# K32W061 register map
Vendor: nxp.com; File version: 1.0
CPU: CM4 r0p1, little endian, MPU, no FPU, VTOR, 3 interrupt priority bits
Registers are 32-bit, read-write, reset 0x0 unless marked. A register's access mark holds for its fields unless they carry their own. Offsets are from the block's base; [hi:lo] are bit positions.

## ASYNC_SYSCON — This is the description of component async_syscon
Base 0x40020000
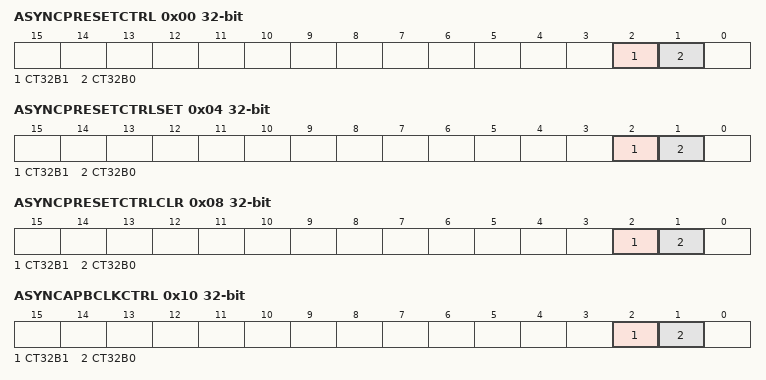
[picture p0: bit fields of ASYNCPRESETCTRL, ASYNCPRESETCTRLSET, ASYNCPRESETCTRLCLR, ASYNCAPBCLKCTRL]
0x00 ASYNCPRESETCTRL — Asynchronous peripherals reset control. The ASYNCPRESETCTRL register allows software to reset specific peripherals attached to the async APB bridge. Writing a zero to any assigned bit in this register clears the reset and allows the specified peripheral to operate. Writing a one asserts the reset.
  [2] CT32B1 — Controls the reset for Counter/Timer CT32B1
    0=CLEAR (Clear reset to Counter/Timer CT32B1.); 1=ASSERT (Assert reset to Counter/Timer CT32B1.)
  [1] CT32B0 — Controls the reset for Counter/Timer CT32B0
    0=CLEAR (Clear reset to Counter/Timer CT32B0.); 1=ASSERT (Assert reset to Counter/Timer CT32B0.)
0x04 ASYNCPRESETCTRLSET reset not defined — Set bits in ASYNCPRESETCTRL. Writing ones to this register sets the corresponding bit or bits in the ASYNCPRESETCTRL register, if they are implemented
  [2] CT32B1 wo — Writing 1 to this register sets the bit ASYNCPRESETCTRL.CT32B1
    0=NO_EFFECT; 1=SET (Set the bit ASYNCPRESETCTRL.CT32B1.)
  [1] CT32B0 wo — Writing 1 to this register sets the bit ASYNCPRESETCTRL.CT32B0
    0=NO_EFFECT; 1=SET (Set the bit ASYNCPRESETCTRL.CT32B0.)
0x08 ASYNCPRESETCTRLCLR reset not defined — Clear bits in ASYNCPRESETCTRL. Writing ones to this register clears the corresponding bit or bits in the ASYNCPRESETCTRL register, if they are implemented
  [2] CT32B1 wo — Writing 1 to this register clears the bit ASYNCPRESETCTRL.CT32B1
    0=NO_EFFECT; 1=CLEAR (Clear the bit ASYNCPRESETCTRL.CT32B1.)
  [1] CT32B0 wo — Writing 1 to this register clears the bit ASYNCPRESETCTRL.CT32B0
    0=NO_EFFECT; 1=CLEAR (Clear the bit ASYNCPRESETCTRL.CT32B0.)
0x10 ASYNCAPBCLKCTRL — Asynchronous peripherals clock control. This register controls how the clock selected for the asynchronous APB peripherals is divided to provide the clock to the asynchronous peripherals
  [2] CT32B1 — Controls the clock for Counter/Timer CT32B1
    0=DISABLE (Disable clock to Counter/Timer CT32B1.); 1=ENABLE (Enable clock to Counter/Timer CT32B1.)
  [1] CT32B0 — Controls the clock for Counter/Timer CT32B0
    0=DISABLE (Disable clock to Counter/Timer CT32B0.); 1=ENABLE (Enable clock to Counter/Timer CT32B0.)
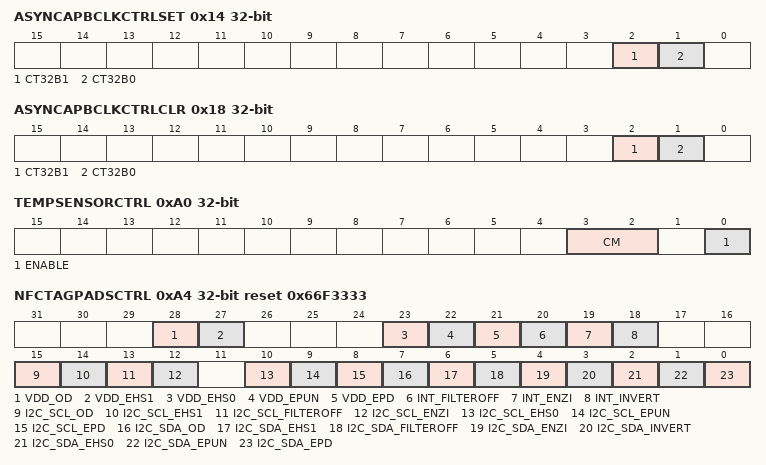
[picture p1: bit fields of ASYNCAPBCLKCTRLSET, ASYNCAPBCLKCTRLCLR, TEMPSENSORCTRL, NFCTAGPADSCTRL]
0x14 ASYNCAPBCLKCTRLSET reset not defined — Set bits in ASYNCAPBCLKCTRL. Writing ones to this register sets the corresponding bit or bits in the ASYNCAPBCLKCTRLSET register, if they are implemented
  [2] CT32B1 wo — Writing 1 to this register sets the bit ASYNCAPBCLKCTRL.CT32B1
    0=NO_EFFECT; 1=SET (Set the bit ASYNCAPBCLKCTRL.CT32B1.)
  [1] CT32B0 wo — Writing 1 to this register sets the bit ASYNCAPBCLKCTRL.CT32B0
    0=NO_EFFECT; 1=SET (Set the bit ASYNCAPBCLKCTRL.CT32B0.)
0x18 ASYNCAPBCLKCTRLCLR reset not defined — Clear bits in ASYNCAPBCLKCTRL. Writing ones to this register sets the corresponding bit or bits in the ASYNCAPBCLKCTRLSET register, if they are implemented
  [2] CT32B1 wo — Writing 1 to this register clears the bit ASYNCAPBCLKCTRL.CT32B1
    0=NO_EFFECT; 1=CLEAR (Clear the bit ASYNCAPBCLKCTRL.CT32B1.)
  [1] CT32B0 wo — Writing 1 to this register clears the bit ASYNCAPBCLKCTRL.CT32B0
    0=NO_EFFECT; 1=CLEAR (Clear the ASYNCAPBCLKCTRL.CT32B0.)
0x20 ASYNCAPBCLKSELA — Asynchronous APB clock source select
  [1:0] SEL — Clock source for modules beyond asynchronous Bus bridge: ASYNC_SYSCON itself, timers 0/1.
    0=MAINCLK (System Bus clock.); 1=XTAL32M (32 MHz crystal oscillator (XTAL32M).); 2=FRO32M (32 MHz free running oscillator (FRO32M).); 3=FRO48M (48 MHz free running oscillator (FRO48M).)
0xA0 TEMPSENSORCTRL — Temperature Sensor controls
  [3:2] CM — Temerature sensor common mode output voltage selection: 0x0: high negative offset added; 0x1: intermediate negative offset added; 0x2: no offset added; 0x3: low positive offset added. Only setting 0x2 should be used.
  [0] ENABLE — Temperature sensor enable
0xA4 NFCTAGPADSCTRL reset 0x66F3333 — NFC Tag pads control for I2C interface to internal NFC Tag (T parts only): I2C interface + 1 interrupt/ field detect input pad + NTAG VDD output pad
  [28] VDD_OD — NTAG VDD open-drain mode control: 0: Normal. Normal push-pull output; 1: Open-drain. Simulated open-drain output (high drive disabled).
  [27] VDD_EHS1 — NTAG VDD IO Driver slew rate MSB. (VDD_EHS1, VDD_EHS0) sets IO cell speed when enabled as an output. 00: Low speed; 01: nominal speed; 10: fast speed; 11: high speed. Recommendation is to use default value (0)
  [23] VDD_EHS0 — NTAG VDD IO Driver slew rate LSB. (VDD_EHS1, VDD_EHS0) sets IO cell speed when enabled as an output. 00=Low speed, 01=nominal speed, 10=fast speed, 11=high speed. Recommendation is to use default value (0)
  [22] VDD_EPUN — NTAG_VDD, Enable weak pull up on IO pad, active low
  [21] VDD_EPD — NTAG VDD, Enable weak pull down on IO pad
  [20] INT_FILTEROFF — Reserved. NTAG INT/FD IO cell always filters signal, not configurable
  [19] INT_ENZI — Reserved. NTAG INT/FD IO cell always enabled, not configurable
  [18] INT_INVERT — NTAG INT/FD Input polarity: 0: Input function is not inverted; 1: Input function is inverted.
  [15] I2C_SCL_OD — I2C_SCL open-drain mode control: 0: Normal. Normal push-pull output; 1: Open-drain. Simulated open-drain output (high drive disabled).
  [14] I2C_SCL_EHS1 — I2C_SCL IO Driver slew rate MSB. (I2C_SCL_EHS1, I2C_SCL_EHS0). RESERVED: use default value (0)
  [13] I2C_SCL_FILTEROFF — I2C_SCL, input glitch filter control: 0: Filter enabled. Short noise pulses are filtered out; 1: Filter disabled. No input filtering is done.
  [12] I2C_SCL_ENZI — I2C_SCL Receiver enable, active high
  [10] I2C_SCL_EHS0 — I2C_SCL IO Driver slew rate LSB. (I2C_SCL_EHS1, I2C_SCL_EHS0). RESERVED: use default value (0)
  [9] I2C_SCL_EPUN — I2C_SCL, Enable weak pull up on IO pad, active low. 0: pullup enabled; 1: pullup disabled.
  [8] I2C_SCL_EPD — I2C_SCL, Enable weak pull down on IO pad. 0: disabled; 1: pull down enabled.
  [7] I2C_SDA_OD — I2C_SDA, Controls open-drain mode. 0 Normal. Normal push-pull output 1 Open-drain. Simulated open-drain output (high drive disabled).
  [6] I2C_SDA_EHS1 — I2C_SDA IO Driver slew rate MSB. (I2C_SDA_EHS1, I2C_SDA_EHS0). RESERVED: use default value (0)
  [5] I2C_SDA_FILTEROFF — I2C_SDA input glitch filter control. 0 Filter enabled. Short noise pulses are filtered out. 1 Filter disabled. No input filtering is done.
  [4] I2C_SDA_ENZI — I2C_SDA Receiver enable, active high
  [3] I2C_SDA_INVERT — I2C_SDA Input polarity. 0 : Input function is not inverted. 1 : Input function is inverted.
  [2] I2C_SDA_EHS0 — I2C_SDA IO Driver slew rate LSB. (I2C_SDA_EHS1, I2C_SDA_EHS0). RESERVED: use default value (0)
  [1] I2C_SDA_EPUN — I2C_SDA, Enable weak pull up on IO pad, active low. 0=pullup enabled. 1=pullup disabled
  [0] I2C_SDA_EPD — I2C_SDA, Enable weak pull down on IO pad. 0= disabled. 1=pull down enabled.
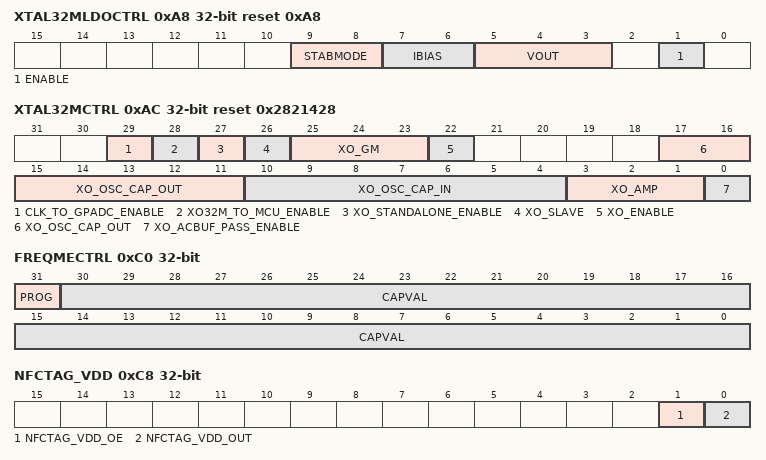
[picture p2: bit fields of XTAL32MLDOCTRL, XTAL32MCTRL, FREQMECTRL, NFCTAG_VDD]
0xA8 XTAL32MLDOCTRL reset 0xA8 — XTAL 32 MHz LDO control register. If XTAL has been auto started due to EFUSE XTAL32MSTART_ENA or BLE low power timers then the effect of these need disabling via SYSCON.XTAL32MCTRL before the full control by this register is possible.
  [9:8] STABMODE — Stability configuration, only required for test purposes.
  [7:6] IBIAS — Adjust the biasing current, setting managed by software API.
  [5:3] VOUT — Adjust the output voltage level, setting managed by software API.
  [1] ENABLE — Enable the LDO when set. Setting managed by software API.
0xAC XTAL32MCTRL reset 0x2821428 — XTAL 32 MHz control register. If XTAL has been auto started due to EFUSE XTAL32MSTART_ENA or BLE low power timers then the effect of these need disabling via SYSCON.XTAL32MCTRL before the full control by this register is possible.
  [29] CLK_TO_GPADC_ENABLE — Enable the 16MHz clock to General Purpose ADC
  [28] XO32M_TO_MCU_ENABLE — Enable the 32MHz clock to MCU and the clock generators.
  [27] XO_STANDALONE_ENABLE — Selection of the LDO and core XO reference biasing sources (1uA bandgap current and 0.6V bandgap voltage): 0: biasing provided by radio reference biasing sources. Don't switch to this value without prior radio biasing, LDO XO, core XO, LDO 1.4V and PLL current distribution enabling. 1: biasing is provided by Power Management Unit (PMU). Control of this bit is generally managed by the radio or clock software functions.
  [26] XO_SLAVE — XTAL in slave mode. Setting managed by software API.
  [25:23] XO_GM — Gm value for XTAL.. Setting managed by software API.
  [22] XO_ENABLE — Enable signal for 32MHz XTAL.
  [17:11] XO_OSC_CAP_OUT — Internal Capacitor Selection for XTAL_N. Each XTAL pin has a capacitance value up to approximately 25pF. Device test calibration data is stored on chip so that a software function can configure a capacitiance with high accuracy.
  [10:4] XO_OSC_CAP_IN — Internal Capacitor Selection for XTAL_P. Each XTAL pin has a capacitance value up to approximately 25pF. Device test calibration data is stored on chip so that a software function can configure a capacitiance with high accuracy.
  [3:1] XO_AMP — Amplitude selection , Min amp: 001, Max amp: 110. Setting managed by software API.
  [0] XO_ACBUF_PASS_ENABLE — Bypass enable of XTAL AC buffer enable in pll and top level. Setting managed by software API.
0xB0 ANALOGID ro reset 0x7 — Analog Interfaces (PMU and Radio) identity registers
  [5:0] PMUID — PMU Identitty register used ti indicate a version of the PMU.
0xB4 RADIOSTATUS ro — All Radio Analog modules status register.
  [0] PLLXOREADY — Value of status output by 32M XTAL oscillator. Aserted to indicate that the clock is active. Note that the quality of the 32M clock may improve even after this is asserted. Additionally, if settings are changed such as ibias control then this status flag will probably remain asserted even though changes to the clock signal will be occuring,
0xBC DCBUSCTRL — DC Bus can be used during device test and evaluation to give observation of internal signals.
  [8:0] ADDR — ADDR[8] should be set to 1 before entering power down to prevent the risk of a small amount of leakage current during power down.
0xC0 FREQMECTRL — Frequency measure register
  [31] PROG — Set this bit to one to initiate a frequency measurement cycle. Hardware clears this bit when the measurement cycle has completed and there is valid capture data in the CAPVAL field (bits 13:0).
  [30:0] CAPVAL — Frequency Measure control and status; the function differs for a read and write operation. CAPVAL: FREQMECTRL[30:0] (Read-only) : Stores the target counter result from the last frequency measure activiation, this is used in the calculation of the unknown clock frequency of the reference or target clock. SCALE: FREQMECTRL[4:0] (Write-only) : define the count duration, (2^SCALE)-1, that reference counter counts to during measurement. Note that the value is 2 giving a minimum count 2^2-1 = 3. The result of freq_me_plus can be calculated as follows : freq_targetclk =freq_refclk* (CAPVAL+1) / ((2^SCALE)-1);
0xC8 NFCTAG_VDD — NFCTAG VDD output control
  [1] NFCTAG_VDD_OE — Output enable for the NFC Tag Vdd IO cell.
  [0] NFCTAG_VDD_OUT — Output value for the NFC Tag Vdd IO, if enabled with NFCTAG_VDD_OE.
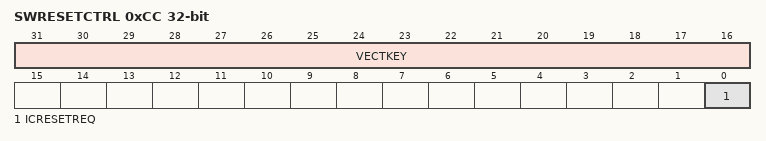
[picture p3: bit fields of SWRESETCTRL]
0xCC SWRESETCTRL reset not defined — Full IC reset request (from Software application).
  [31:16] VECTKEY wo — Register Key: On write, write 0x05FA to VECTKEY, otherwise the write is ignored.
  [0] ICRESETREQ wo — IC reset request. This bit is only valid if VECTKEY is set correctly. 0: No effect; 1: Request a fulll IC reset level reset
